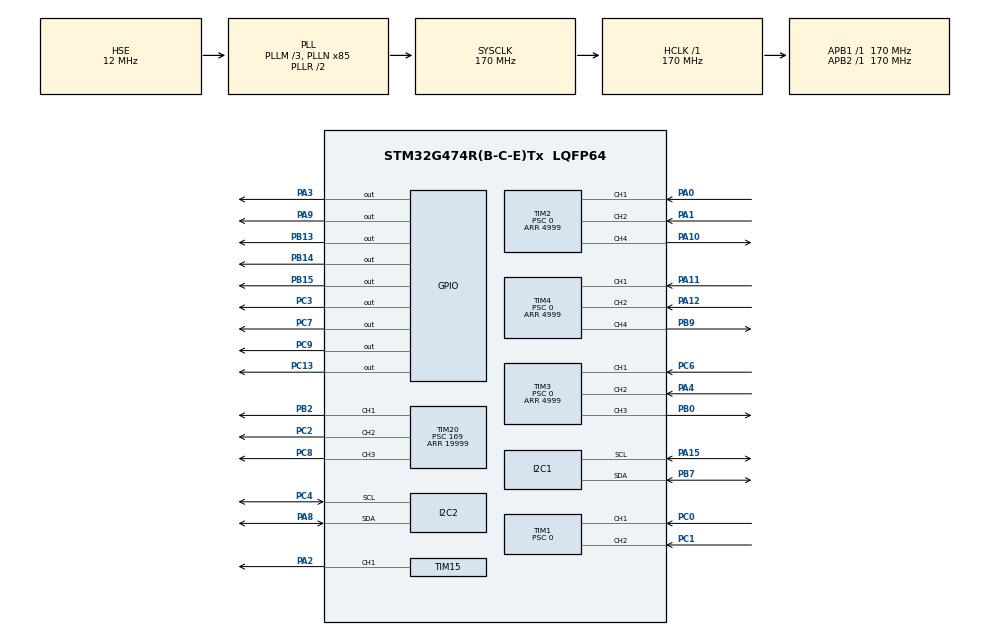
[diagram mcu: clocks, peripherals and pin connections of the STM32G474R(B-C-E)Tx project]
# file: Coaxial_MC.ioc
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FREERTOS.MEMORY_ALLOCATION=2
FREERTOS.Tasks01=cmdTask,0,128,StartCmdTask,Default,NULL,Dynamic,NULL,NULL
I2C1.Timing=0x30A0A7FB
I2C2.Timing=0x30A0A7FB
Mcu.Family=STM32G4
Mcu.Name=STM32G474R(B-C-E)Tx
Mcu.Package=LQFP64
NVIC.PriorityGroup=NVIC_PRIORITYGROUP_4
NVIC.TIM1_BRK_TIM15_IRQn=true\:5\:0\:false\:false\:true\:true\:true\:true\:true
NVIC.TIM1_UP_TIM16_IRQn=true\:5\:0\:false\:false\:true\:false\:false\:true\:true
NVIC.TIM20_BRK_IRQn=true\:5\:0\:false\:false\:true\:true\:true\:true\:true
NVIC.TIM20_CC_IRQn=true\:5\:0\:false\:false\:true\:true\:true\:true\:true
NVIC.TIM20_UP_IRQn=true\:5\:0\:false\:false\:true\:true\:true\:true\:true
NVIC.TIM2_IRQn=true\:5\:0\:false\:false\:true\:true\:true\:true\:true
NVIC.TIM3_IRQn=true\:5\:0\:false\:false\:true\:true\:true\:true\:true
NVIC.TIM4_IRQn=true\:5\:0\:false\:false\:true\:true\:true\:true\:true
NVIC.TIM6_DAC_IRQn=true\:5\:0\:false\:false\:true\:true\:true\:true\:true
NVIC.TimeBase=TIM1_UP_TIM16_IRQn
NVIC.TimeBaseIP=TIM16
PA0.GPIO_PuPd=GPIO_PULLUP
PA0.Signal=S_TIM2_CH1
PA1.GPIO_PuPd=GPIO_PULLUP
PA1.Signal=S_TIM2_CH2
PA10.Signal=S_TIM2_CH4
PA11.GPIO_PuPd=GPIO_NOPULL
PA11.Signal=S_TIM4_CH1
PA12.GPIO_PuPd=GPIO_NOPULL
PA12.Signal=S_TIM4_CH2
PA13.Mode=Serial_Wire
PA13.Signal=SYS_JTMS-SWDIO
PA14.Mode=Serial_Wire
PA14.Signal=SYS_JTCK-SWCLK
PA15.Mode=I2C
PA15.Signal=I2C1_SCL
PA2.Signal=S_TIM15_CH1
PA3.Signal=GPIO_Output
PA4.GPIO_PuPd=GPIO_PULLUP
PA4.Signal=S_TIM3_CH2
PA8.Mode=I2C
PA8.Signal=I2C2_SDA
PA9.Signal=GPIO_Output
PB0.Signal=S_TIM3_CH3
PB13.Signal=GPIO_Output
PB14.Signal=GPIO_Output
PB15.Signal=GPIO_Output
PB2.Signal=S_TIM20_CH1
PB7.Mode=I2C
PB7.Signal=I2C1_SDA
PB9.Signal=S_TIM4_CH4
PC0.GPIO_PuPd=GPIO_PULLUP
PC0.Signal=S_TIM1_CH1
PC1.GPIO_PuPd=GPIO_PULLUP
PC1.Signal=S_TIM1_CH2
PC13.Signal=GPIO_Output
PC2.Signal=S_TIM20_CH2
PC3.Signal=GPIO_Output
PC4.Mode=I2C
PC4.Signal=I2C2_SCL
PC6.GPIO_PuPd=GPIO_PULLUP
PC6.Signal=S_TIM3_CH1
PC7.Signal=GPIO_Output
PC8.Signal=S_TIM20_CH3
PC9.Signal=GPIO_Output
PF0-OSC_IN.Mode=HSE-External-Oscillator
PF0-OSC_IN.Signal=RCC_OSC_IN
PF1-OSC_OUT.Mode=HSE-External-Oscillator
PF1-OSC_OUT.Signal=RCC_OSC_OUT
ProjectManager.HeapSize=0x200
ProjectManager.StackSize=0x400
ProjectManager.TargetToolchain=Makefile
RCC.ADC12Freq_Value=170000000
RCC.ADC345Freq_Value=170000000
RCC.AHBFreq_Value=170000000
RCC.APB1Freq_Value=170000000
RCC.APB1TimFreq_Value=170000000
RCC.APB2Freq_Value=170000000
RCC.APB2TimFreq_Value=170000000
RCC.CortexFreq_Value=170000000
RCC.EXTERNAL_CLOCK_VALUE=12288000
RCC.HCLKFreq_Value=170000000
RCC.HSE_VALUE=12000000
RCC.HSI48_VALUE=48000000
RCC.HSI_VALUE=16000000
RCC.LSE_VALUE=32768
RCC.PLLM=RCC_PLLM_DIV3
RCC.PLLN=85
RCC.PLLSourceVirtual=RCC_PLLSOURCE_HSE
RCC.SYSCLKFreq_VALUE=170000000
RCC.SYSCLKSource=RCC_SYSCLKSOURCE_PLLCLK
RCC.USBFreq_Value=170000000
RCC.VCOOutputFreq_Value=340000000
SH.S_TIM15_CH1.0=TIM15_CH1,PWM Generation1 CH1
SH.S_TIM1_CH1.0=TIM1_CH1,Encoder_Interface
SH.S_TIM1_CH2.0=TIM1_CH2,Encoder_Interface
SH.S_TIM20_CH1.0=TIM20_CH1,PWM Generation1 CH1
SH.S_TIM20_CH2.0=TIM20_CH2,PWM Generation2 CH2
SH.S_TIM20_CH3.0=TIM20_CH3,PWM Generation3 CH3
SH.S_TIM2_CH1.0=TIM2_CH1,Encoder_Interface
SH.S_TIM2_CH2.0=TIM2_CH2,Encoder_Interface
SH.S_TIM2_CH4.0=TIM2_CH4,PWM Generation4 CH4
SH.S_TIM3_CH1.0=TIM3_CH1,Encoder_Interface
SH.S_TIM3_CH2.0=TIM3_CH2,Encoder_Interface
SH.S_TIM3_CH3.0=TIM3_CH3,PWM Generation3 CH3
SH.S_TIM4_CH1.0=TIM4_CH1,Encoder_Interface
SH.S_TIM4_CH2.0=TIM4_CH2,Encoder_Interface
SH.S_TIM4_CH4.0=TIM4_CH4,PWM Generation4 CH4
TIM1.AutoReloadPreload=TIM_AUTORELOAD_PRELOAD_ENABLE
TIM1.EncoderMode=TIM_ENCODERMODE_TI12
TIM1.PeriodNoDither=4999
TIM1.Prescaler=0
TIM15.AutoReloadPreload=TIM_AUTORELOAD_PRELOAD_ENABLE
TIM15.Channel-PWM\ Generation1\ CH1=TIM_CHANNEL_1
TIM15.PeriodNoDither=4999
TIM15.Prescaler=0
TIM2.AutoReloadPreload=TIM_AUTORELOAD_PRELOAD_ENABLE
TIM2.Channel-PWM\ Generation4\ CH4=TIM_CHANNEL_4
TIM2.EncoderMode=TIM_ENCODERMODE_TI12
TIM2.PeriodNoDither=4999
TIM2.Prescaler=0
TIM20.AutoReloadPreload=TIM_AUTORELOAD_PRELOAD_ENABLE
TIM20.Channel-PWM\ Generation1\ CH1=TIM_CHANNEL_1
TIM20.Channel-PWM\ Generation2\ CH2=TIM_CHANNEL_2
TIM20.Channel-PWM\ Generation3\ CH3=TIM_CHANNEL_3
TIM20.PeriodNoDither=19999
TIM20.Prescaler=169
TIM3.AutoReloadPreload=TIM_AUTORELOAD_PRELOAD_ENABLE
TIM3.Channel-PWM\ Generation3\ CH3=TIM_CHANNEL_3
TIM3.EncoderMode=TIM_ENCODERMODE_TI12
TIM3.PeriodNoDither=4999
TIM3.Prescaler=0
TIM4.AutoReloadPreload=TIM_AUTORELOAD_PRELOAD_ENABLE
TIM4.Channel-PWM\ Generation4\ CH4=TIM_CHANNEL_4
TIM4.EncoderMode=TIM_ENCODERMODE_TI12
TIM4.OCFastMode_PWM-PWM\ Generation4\ CH4=TIM_OCFAST_DISABLE
TIM4.PeriodNoDither=4999
TIM4.Prescaler=0
TIM6.PeriodNoDither=24
TIM6.Prescaler=84
VP_FREERTOS_VS_CMSIS_V1.Mode=CMSIS_V1
VP_SYS_VS_DBSignals.Mode=DisableDeadBatterySignals
VP_SYS_VS_tim16.Mode=TIM16
VP_TIM17_VS_ClockSourceINT.Mode=Enable_Timer
VP_TIM6_VS_ClockSourceINT.Mode=Enable_Timer
board=custom

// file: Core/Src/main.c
/* USER CODE BEGIN Header */
/**
  ******************************************************************************
  * @file           : main.c
  * @brief          : Main program body
  ******************************************************************************
  * @attention
  *
  * Copyright (c) 2024 STMicroelectronics.
  * All rights reserved.
  *
  * This software is licensed under terms that can be found in the LICENSE file
  * in the root directory of this software component.
  * If no LICENSE file comes with this software, it is provided AS-IS.
  *
  ******************************************************************************
  */
/* USER CODE END Header */
#include "main.h"
#include "cmsis_os.h"
#include "i2c.h"
#include "tim.h"
#include "gpio.h"

/* USER CODE BEGIN Includes */
#include "robot.h"
#include "robot_def.h"
/* USER CODE END Includes */

void SystemClock_Config(void);
void MX_FREERTOS_Init(void);

int main(void)
{

  /* MCU Configuration--------------------------------------------------------*/

  /* Reset of all peripherals, Initializes the Flash interface and the Systick. */
  HAL_Init();

  /* Configure the system clock */
  SystemClock_Config();

  /* Initialize all configured peripherals */
  MX_GPIO_Init();
  MX_TIM1_Init();
  MX_TIM2_Init();
  MX_TIM3_Init();
  MX_TIM4_Init();
  MX_TIM15_Init();
  MX_TIM20_Init();
  MX_I2C1_Init();
  MX_I2C2_Init();
  MX_TIM6_Init();
  MX_TIM17_Init();
  /* USER CODE BEGIN 2 */
  RobotInit();
  HAL_TIM_Base_Start_IT(&htim6); /* 开启定时器6定时中断 */
  /* USER CODE END 2 */

  /* Call init function for freertos objects (in cmsis_os2.c) */
  MX_FREERTOS_Init();

  /* Start scheduler */
  osKernelStart();

  /* We should never get here as control is now taken by the scheduler */

  /* Infinite loop */
  while (1)
  {

  }
}

void SystemClock_Config(void)
{
  RCC_OscInitTypeDef RCC_OscInitStruct = {0};
  RCC_ClkInitTypeDef RCC_ClkInitStruct = {0};

  /** Configure the main internal regulator output voltage
  */
  HAL_PWREx_ControlVoltageScaling(PWR_REGULATOR_VOLTAGE_SCALE1_BOOST);

  /** Initializes the RCC Oscillators according to the specified parameters
  * in the RCC_OscInitTypeDef structure.
  */
  RCC_OscInitStruct.OscillatorType = RCC_OSCILLATORTYPE_HSE;
  RCC_OscInitStruct.HSEState = RCC_HSE_ON;
  RCC_OscInitStruct.PLL.PLLState = RCC_PLL_ON;
  RCC_OscInitStruct.PLL.PLLSource = RCC_PLLSOURCE_HSE;
  RCC_OscInitStruct.PLL.PLLM = RCC_PLLM_DIV3;
  RCC_OscInitStruct.PLL.PLLN = 85;
  RCC_OscInitStruct.PLL.PLLP = RCC_PLLP_DIV2;
  RCC_OscInitStruct.PLL.PLLQ = RCC_PLLQ_DIV2;
  RCC_OscInitStruct.PLL.PLLR = RCC_PLLR_DIV2;
  if (HAL_RCC_OscConfig(&RCC_OscInitStruct) != HAL_OK)
  {
    Error_Handler();
  }

  /** Initializes the CPU, AHB and APB buses clocks
  */
  RCC_ClkInitStruct.ClockType = RCC_CLOCKTYPE_HCLK|RCC_CLOCKTYPE_SYSCLK
                              |RCC_CLOCKTYPE_PCLK1|RCC_CLOCKTYPE_PCLK2;
  RCC_ClkInitStruct.SYSCLKSource = RCC_SYSCLKSOURCE_PLLCLK;
  RCC_ClkInitStruct.AHBCLKDivider = RCC_SYSCLK_DIV1;
  RCC_ClkInitStruct.APB1CLKDivider = RCC_HCLK_DIV1;
  RCC_ClkInitStruct.APB2CLKDivider = RCC_HCLK_DIV1;

  if (HAL_RCC_ClockConfig(&RCC_ClkInitStruct, FLASH_LATENCY_4) != HAL_OK)
  {
    Error_Handler();
  }
}

void HAL_TIM_PeriodElapsedCallback(TIM_HandleTypeDef *htim)
{
  /* USER CODE BEGIN Callback 0 */
  if(htim->Instance == TIM6)
    {
      // MotorRun(MOTOR_LEFT);
      // MotorControlCwCCw(MOTOR_LEFT, MOTOR_CCW);
      // __HAL_TIM_SET_COMPARE(&htim4, TIM_CHANNEL_4, 4599);
    }
  /* USER CODE END Callback 0 */
  if (htim->Instance == TIM16) {
    HAL_IncTick();
  }
}

void Error_Handler(void)
{
  __disable_irq();
  while (1)
  {
  }
}

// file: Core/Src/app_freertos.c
/* USER CODE BEGIN Header */
/**
  ******************************************************************************
  * File Name          : app_freertos.c
  * Description        : Code for freertos applications
  ******************************************************************************
  * @attention
  *
  * Copyright (c) 2024 STMicroelectronics.
  * All rights reserved.
  *
  * This software is licensed under terms that can be found in the LICENSE file
  * in the root directory of this software component.
  * If no LICENSE file comes with this software, it is provided AS-IS.
  *
  ******************************************************************************
  */
/* USER CODE END Header */

#include "FreeRTOS.h"
#include "task.h"
#include "main.h"
#include "cmsis_os.h"

/* USER CODE BEGIN Includes */
#include "robot.h"
/* USER CODE END Includes */

osThreadId cmdTaskHandle;

void StartCmdTask(void const * argument);

void MX_FREERTOS_Init(void); /* (MISRA C 2004 rule 8.1) */

/* GetIdleTaskMemory prototype (linked to static allocation support) */
void vApplicationGetIdleTaskMemory( StaticTask_t **ppxIdleTaskTCBBuffer, StackType_t **ppxIdleTaskStackBuffer, uint32_t *pulIdleTaskStackSize );

/* USER CODE BEGIN GET_IDLE_TASK_MEMORY */
static StaticTask_t xIdleTaskTCBBuffer;
static StackType_t xIdleStack[configMINIMAL_STACK_SIZE];

void vApplicationGetIdleTaskMemory( StaticTask_t **ppxIdleTaskTCBBuffer, StackType_t **ppxIdleTaskStackBuffer, uint32_t *pulIdleTaskStackSize )
{
  *ppxIdleTaskTCBBuffer = &xIdleTaskTCBBuffer;
  *ppxIdleTaskStackBuffer = &xIdleStack[0];
  *pulIdleTaskStackSize = configMINIMAL_STACK_SIZE;
  /* place for user code */
}
/* USER CODE END GET_IDLE_TASK_MEMORY */

void MX_FREERTOS_Init(void) {

  /* Create the thread(s) */
  /* definition and creation of cmdTask */
  osThreadDef(cmdTask, StartCmdTask, osPriorityNormal, 0, 128);
  cmdTaskHandle = osThreadCreate(osThread(cmdTask), NULL);

}

void StartCmdTask(void const * argument)
{
  /* USER CODE BEGIN StartCmdTask */
  /* Infinite loop */
  for(;;)
  {
      HAL_GPIO_TogglePin(GPIOC, GPIO_PIN_13);
      osDelay(1000);
  }
  /* USER CODE END StartCmdTask */
}
